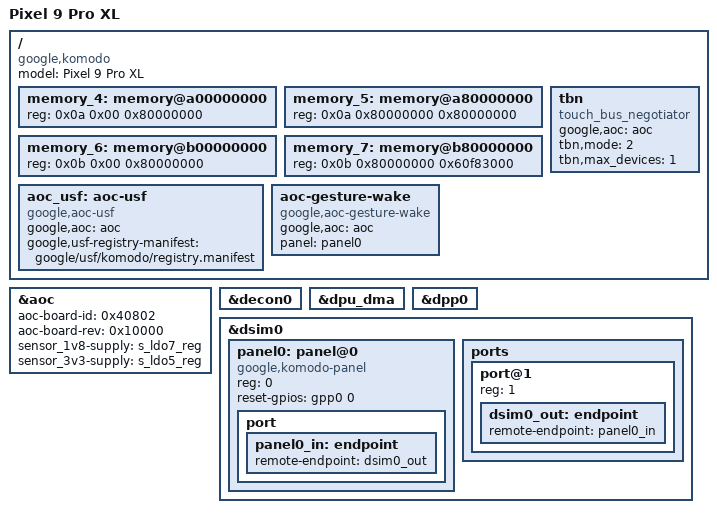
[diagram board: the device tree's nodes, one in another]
// SPDX-License-Identifier: GPL-2.0-only
/*
 * Pixel 9 Pro XL (komodo) Device Tree
 *
 * Copyright 2025 Trijal Saha - <trijalsaha2012@gmail.com>
 */

/dts-v1/;

#include "zumapro-pixel-common.dtsi"
#include "zumapro-caimito-bcm4390.dtsi"
#include "zumapro-caimito-s5400.dtsi"
#include "zumapro-caimito-cs35l41.dtsi"

/ {
	model = "Pixel 9 Pro XL";
	compatible = "google,komodo", "google,zumapro-komodo", "google,zumapro";

	memory_4: memory@a00000000 {
		device_type = "memory";
		reg = <0x0a 0x00 0x80000000>;
	};

	memory_5: memory@a80000000 {
		device_type = "memory";
		reg = <0x0a 0x80000000 0x80000000>;
	};

	memory_6: memory@b00000000 {
		device_type = "memory";
		reg = <0x0b 0x00 0x80000000>;
	};

	memory_7: memory@b80000000 {
		device_type = "memory";
		reg = <0x0b 0x80000000 0x60f83000>;
	};
};

/* Board identity the AOC firmware reads at boot. */
&aoc {
	aoc-board-id = <0x40802>;
	aoc-board-rev = <0x10000>;

	/*
	 * The rails the AoC's physical sensors hang off.  The AoC does not
	 * switch these itself, and without them its sensor stack enumerates
	 * only the fused and software sensors -- the LSM6DSV, magnetometer,
	 * barometer and proximity chips never answer.  Mapping matches the
	 * downstream komodo aoc@17000000: sensor_1v8 = L7S_SENSORS (LDO7S),
	 * sensor_3v3 = L5S_PROX (LDO5S).
	 */
	sensor_1v8-supply = <&s_ldo7_reg>;
	sensor_3v3-supply = <&s_ldo5_reg>;
};

/ {
	/*
	 * Touch Bus Negotiator.  tbn,mode = 2 is the AoC-channel handshake: the
	 * AP <-> AoC arbitration runs as messages over the com.google.tbn_service AoC
	 * service rather than over GPIOs, which is what the downstream tbn node
	 * describes.  One consumer, the touch controller.
	 */
	tbn: tbn {
		compatible = "touch_bus_negotiator";
		google,aoc = <&aoc>;
		tbn,mode = <2>;
		tbn,max_devices = <1>;
	};

	/*
	 * The AoC sensor hub, bridged to IIO.  No hardware is described here: the
	 * sensors live in AoC firmware behind the com.google.usf service.  The driver
	 * uploads the sensor registry itself before enumerating -- the scripts are the
	 * vendor .reg files, staged into the firmware path and listed, in upload
	 * order, by google/usf/komodo/registry.manifest.  Point
	 * google,usf-registry-manifest elsewhere, or list the files directly in
	 * google,usf-registry, to override.
	 */
	aoc_usf: aoc-usf {
		compatible = "google,aoc-usf";
		google,aoc = <&aoc>;
		google,usf-registry-manifest = "google/usf/komodo/registry.manifest";
	};

	/*
	 * Wake gestures the AoC watches while the AP sleeps: a tap on the dark panel,
	 * and lift-to-wake, reported as KEY_WAKEUP.  Armed only while the panel it
	 * names is off.
	 */
	aoc-gesture-wake {
		compatible = "google,aoc-gesture-wake";
		google,aoc = <&aoc>;
		panel = <&panel0>;
	};
};

// &cont_splash_mem {
// 	// reg = <0x0 0xfac00000 (1440 * 3120 * 4)>;
// 	reg = <0x0 0xfac00000 (1344 * 2992 * 4)>;
//
// 	status = "okay";
// };

// &framebuffer0 {
// 	// width = <1440>;
// 	// height = <3120>;
// 	// stride = <(1440 * 4)>;
// 	width = <1344>;
// 	height = <2992>;
// 	stride = <(1344 * 4)>;
// 	format = "a8r8g8b8";
//
// 	status = "okay";
// };

/*
 * Display (DPU) bring-up for komodo.
 *
 * The DECON0/DPP/DPU-DMA/DSIM0 topology is defined in zumapro.dtsi; this
 * board section enables it and attaches the komodo (google,gs-km4) panel via
 * a minimal boot-handoff panel driver (google,komodo-panel).
 *
 * The bootloader initialises the DCPHY, DSIM link and panel and leaves the
 * (dual-DSC, command-mode) link streaming - that is what the simple-
 * framebuffer splash draws into. The DECON DRM stack takes over scanning its
 * own framebuffer into that running link (the DECON emits the matching
 * dual-DSC stream). Disable the simple-framebuffer (and the decon-autorefresh
 * mmio-init) before relying on the DECON output, since enabling decon0 runs
 * decon_reset() and tears the bootloader splash down.
 */
&decon0 {
	status = "okay";
};

&dpu_dma {
	status = "okay";
};

&dpp0 {
	status = "okay";
};

&dsim0 {
	status = "okay";

	panel0: panel@0 {
		compatible = "google,komodo-panel";
		reg = <0>;
		/* DDIC reset for cold power-on (unused on boot handover) */
		reset-gpios = <&gpp0 0 GPIO_ACTIVE_HIGH>;

		port {
			panel0_in: endpoint {
				remote-endpoint = <&dsim0_out>;
			};
		};
	};

	ports {
		port@1 {
			reg = <1>;
			dsim0_out: endpoint {
				remote-endpoint = <&panel0_in>;
			};
		};
	};
};
